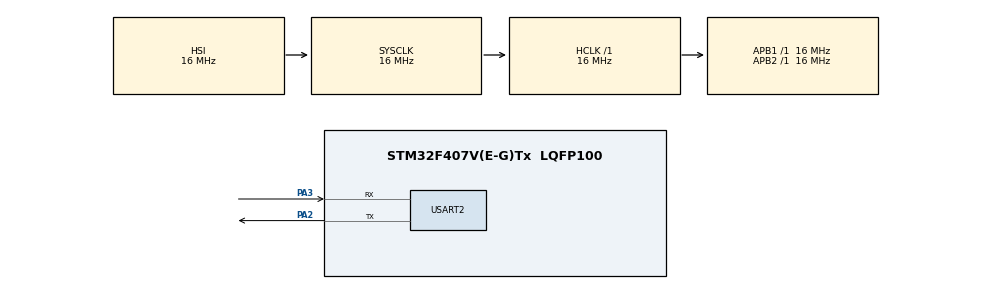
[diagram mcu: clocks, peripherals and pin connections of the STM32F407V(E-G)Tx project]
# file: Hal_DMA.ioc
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Dma.MEMTOMEM.2.Direction=DMA_MEMORY_TO_MEMORY
Dma.MEMTOMEM.2.FIFOMode=DMA_FIFOMODE_ENABLE
Dma.MEMTOMEM.2.FIFOThreshold=DMA_FIFO_THRESHOLD_FULL
Dma.MEMTOMEM.2.Instance=DMA2_Stream0
Dma.MEMTOMEM.2.MemBurst=DMA_MBURST_SINGLE
Dma.MEMTOMEM.2.MemDataAlignment=DMA_MDATAALIGN_BYTE
Dma.MEMTOMEM.2.MemInc=DMA_MINC_ENABLE
Dma.MEMTOMEM.2.Mode=DMA_NORMAL
Dma.MEMTOMEM.2.PeriphBurst=DMA_PBURST_SINGLE
Dma.MEMTOMEM.2.PeriphDataAlignment=DMA_PDATAALIGN_BYTE
Dma.MEMTOMEM.2.PeriphInc=DMA_PINC_ENABLE
Dma.MEMTOMEM.2.Priority=DMA_PRIORITY_LOW
Dma.Request0=USART2_RX
Dma.Request1=USART2_TX
Dma.Request2=MEMTOMEM
Dma.USART2_RX.0.Direction=DMA_PERIPH_TO_MEMORY
Dma.USART2_RX.0.FIFOMode=DMA_FIFOMODE_DISABLE
Dma.USART2_RX.0.Instance=DMA1_Stream5
Dma.USART2_RX.0.MemDataAlignment=DMA_MDATAALIGN_BYTE
Dma.USART2_RX.0.MemInc=DMA_MINC_ENABLE
Dma.USART2_RX.0.Mode=DMA_NORMAL
Dma.USART2_RX.0.PeriphDataAlignment=DMA_PDATAALIGN_BYTE
Dma.USART2_RX.0.PeriphInc=DMA_PINC_DISABLE
Dma.USART2_RX.0.Priority=DMA_PRIORITY_LOW
Dma.USART2_TX.1.Direction=DMA_MEMORY_TO_PERIPH
Dma.USART2_TX.1.FIFOMode=DMA_FIFOMODE_DISABLE
Dma.USART2_TX.1.Instance=DMA1_Stream6
Dma.USART2_TX.1.MemDataAlignment=DMA_MDATAALIGN_BYTE
Dma.USART2_TX.1.MemInc=DMA_MINC_ENABLE
Dma.USART2_TX.1.Mode=DMA_NORMAL
Dma.USART2_TX.1.PeriphDataAlignment=DMA_PDATAALIGN_BYTE
Dma.USART2_TX.1.PeriphInc=DMA_PINC_DISABLE
Dma.USART2_TX.1.Priority=DMA_PRIORITY_LOW
Mcu.Family=STM32F4
Mcu.Name=STM32F407V(E-G)Tx
Mcu.Package=LQFP100
NVIC.DMA1_Stream5_IRQn=true\:0\:0\:false\:false\:true\:false\:true
NVIC.DMA1_Stream6_IRQn=true\:0\:0\:false\:false\:true\:false\:true
NVIC.DMA2_Stream0_IRQn=true\:0\:0\:false\:false\:true\:true\:true
NVIC.PriorityGroup=NVIC_PRIORITYGROUP_4
NVIC.USART2_IRQn=true\:0\:0\:false\:false\:true\:true\:true
PA2.Mode=Asynchronous
PA2.Signal=USART2_TX
PA3.Mode=Asynchronous
PA3.Signal=USART2_RX
ProjectManager.HeapSize=0x200
ProjectManager.StackSize=0x400
ProjectManager.TargetToolchain=MDK-ARM V5
RCC.AHBFreq_Value=16000000
RCC.APB1Freq_Value=16000000
RCC.APB2Freq_Value=16000000
RCC.CortexFreq_Value=16000000
RCC.HSE_VALUE=25000000
RCC.HSI_VALUE=16000000
RCC.LSE_VALUE=32768
RCC.SYSCLKFreq_VALUE=16000000
RCC.VCOOutputFreq_Value=192000000
USART2.VirtualMode=VM_ASYNC
board=custom

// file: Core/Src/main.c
/* USER CODE BEGIN Header */
/**
  ******************************************************************************
  * @file           : main.c

******************************************************************************
  * @attention
  *
  * <h2><center>&copy; Copyright (c) 2021 STMicroelectronics.
  * All rights reserved.</center></h2>
  *
  * This software component is licensed by ST under BSD 3-Clause license,
  * the "License"; You may not use this file except in compliance with the
  * License. You may obtain a copy of the License at:
  *                        opensource.org/licenses/BSD-3-Clause
  *
  ******************************************************************************
  */
/* USER CODE END Header */
#include "main.h"

UART_HandleTypeDef huart2;
DMA_HandleTypeDef hdma_usart2_rx;
DMA_HandleTypeDef hdma_usart2_tx;

DMA_HandleTypeDef hdma_memtomem_dma2_stream0;
/* USER CODE BEGIN PV */
uint8_t Data[10];
uint8_t DataTX[10];
/* USER CODE END PV */

void SystemClock_Config(void);
static void MX_GPIO_Init(void);
static void MX_DMA_Init(void);
static void MX_USART2_UART_Init(void);

int main(void)
{

  /* MCU Configuration--------------------------------------------------------*/

  /* Reset of all peripherals, Initializes the Flash interface and the Systick. */
  HAL_Init();

  /* Configure the system clock */
  SystemClock_Config();

  /* Initialize all configured peripherals */
  MX_GPIO_Init();
  MX_DMA_Init();
  MX_USART2_UART_Init();
  /* USER CODE BEGIN 2 */
	HAL_UART_Receive_DMA(&huart2, (uint8_t *)&Data, 10);
  /* USER CODE END 2 */

  /* Infinite loop */
  while (1)
  {

  }
}

void SystemClock_Config(void)
{
  RCC_OscInitTypeDef RCC_OscInitStruct = {0};
  RCC_ClkInitTypeDef RCC_ClkInitStruct = {0};

  /** Configure the main internal regulator output voltage
  */
  __HAL_RCC_PWR_CLK_ENABLE();
  __HAL_PWR_VOLTAGESCALING_CONFIG(PWR_REGULATOR_VOLTAGE_SCALE1);
  /** Initializes the RCC Oscillators according to the specified parameters
  * in the RCC_OscInitTypeDef structure.
  */
  RCC_OscInitStruct.OscillatorType = RCC_OSCILLATORTYPE_HSI;
  RCC_OscInitStruct.HSIState = RCC_HSI_ON;
  RCC_OscInitStruct.HSICalibrationValue = RCC_HSICALIBRATION_DEFAULT;
  RCC_OscInitStruct.PLL.PLLState = RCC_PLL_NONE;
  if (HAL_RCC_OscConfig(&RCC_OscInitStruct) != HAL_OK)
  {
    Error_Handler();
  }
  /** Initializes the CPU, AHB and APB buses clocks
  */
  RCC_ClkInitStruct.ClockType = RCC_CLOCKTYPE_HCLK|RCC_CLOCKTYPE_SYSCLK
                              |RCC_CLOCKTYPE_PCLK1|RCC_CLOCKTYPE_PCLK2;
  RCC_ClkInitStruct.SYSCLKSource = RCC_SYSCLKSOURCE_HSI;
  RCC_ClkInitStruct.AHBCLKDivider = RCC_SYSCLK_DIV1;
  RCC_ClkInitStruct.APB1CLKDivider = RCC_HCLK_DIV1;
  RCC_ClkInitStruct.APB2CLKDivider = RCC_HCLK_DIV1;

  if (HAL_RCC_ClockConfig(&RCC_ClkInitStruct, FLASH_LATENCY_0) != HAL_OK)
  {
    Error_Handler();
  }
}

static void MX_USART2_UART_Init(void)
{

  huart2.Instance = USART2;
  huart2.Init.BaudRate = 115200;
  huart2.Init.WordLength = UART_WORDLENGTH_8B;
  huart2.Init.StopBits = UART_STOPBITS_1;
  huart2.Init.Parity = UART_PARITY_NONE;
  huart2.Init.Mode = UART_MODE_TX_RX;
  huart2.Init.HwFlowCtl = UART_HWCONTROL_NONE;
  huart2.Init.OverSampling = UART_OVERSAMPLING_16;
  if (HAL_UART_Init(&huart2) != HAL_OK)
  {
    Error_Handler();
  }

}

static void MX_DMA_Init(void)
{

  /* DMA controller clock enable */
  __HAL_RCC_DMA1_CLK_ENABLE();
  __HAL_RCC_DMA2_CLK_ENABLE();

  /* Configure DMA request hdma_memtomem_dma2_stream0 on DMA2_Stream0 */
  hdma_memtomem_dma2_stream0.Instance = DMA2_Stream0;
  hdma_memtomem_dma2_stream0.Init.Channel = DMA_CHANNEL_0;
  hdma_memtomem_dma2_stream0.Init.Direction = DMA_MEMORY_TO_MEMORY;
  hdma_memtomem_dma2_stream0.Init.PeriphInc = DMA_PINC_ENABLE;
  hdma_memtomem_dma2_stream0.Init.MemInc = DMA_MINC_ENABLE;
  hdma_memtomem_dma2_stream0.Init.PeriphDataAlignment = DMA_PDATAALIGN_BYTE;
  hdma_memtomem_dma2_stream0.Init.MemDataAlignment = DMA_MDATAALIGN_BYTE;
  hdma_memtomem_dma2_stream0.Init.Mode = DMA_NORMAL;
  hdma_memtomem_dma2_stream0.Init.Priority = DMA_PRIORITY_LOW;
  hdma_memtomem_dma2_stream0.Init.FIFOMode = DMA_FIFOMODE_ENABLE;
  hdma_memtomem_dma2_stream0.Init.FIFOThreshold = DMA_FIFO_THRESHOLD_FULL;
  hdma_memtomem_dma2_stream0.Init.MemBurst = DMA_MBURST_SINGLE;
  hdma_memtomem_dma2_stream0.Init.PeriphBurst = DMA_PBURST_SINGLE;
  if (HAL_DMA_Init(&hdma_memtomem_dma2_stream0) != HAL_OK)
  {
    Error_Handler( );
  }

  /* DMA interrupt init */
  /* DMA1_Stream5_IRQn interrupt configuration */
  HAL_NVIC_SetPriority(DMA1_Stream5_IRQn, 0, 0);
  HAL_NVIC_EnableIRQ(DMA1_Stream5_IRQn);
  /* DMA1_Stream6_IRQn interrupt configuration */
  HAL_NVIC_SetPriority(DMA1_Stream6_IRQn, 0, 0);
  HAL_NVIC_EnableIRQ(DMA1_Stream6_IRQn);
  /* DMA2_Stream0_IRQn interrupt configuration */
  HAL_NVIC_SetPriority(DMA2_Stream0_IRQn, 0, 0);
  HAL_NVIC_EnableIRQ(DMA2_Stream0_IRQn);

}

static void MX_GPIO_Init(void)
{

  /* GPIO Ports Clock Enable */
  __HAL_RCC_GPIOA_CLK_ENABLE();

}

/* USER CODE BEGIN 4 */
void HAL_UART_TxCpltCallback (UART_HandleTypeDef *huart)
{
	if (huart == &huart2)
	{
		HAL_UART_Receive_DMA(&huart2, (uint8_t *)&Data, 10);
	}
}

void HAL_UART_RxCpltCallback (UART_HandleTypeDef *huart)
{
	if (huart == &huart2)
	{
		HAL_DMA_Start_IT(&hdma_memtomem_dma2_stream0, (uint32_t)&Data, (uint32_t)&DataTX, 10);
	}
}

/* USER CODE END 4 */

void Error_Handler(void)
{
  __disable_irq();
  while (1)
  {
  }
}

/************************ (C) COPYRIGHT STMicroelectronics *****END OF FILE****/
